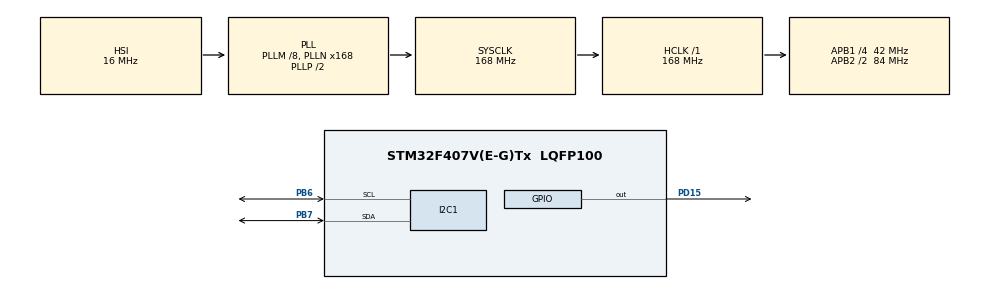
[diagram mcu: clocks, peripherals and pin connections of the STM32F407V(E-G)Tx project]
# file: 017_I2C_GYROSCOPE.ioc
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I2C1.I2C_Mode=I2C_Fast
Mcu.Family=STM32F4
Mcu.Name=STM32F407V(E-G)Tx
Mcu.Package=LQFP100
NVIC.PriorityGroup=NVIC_PRIORITYGROUP_4
PB6.Mode=I2C
PB6.Signal=I2C1_SCL
PB7.Mode=I2C
PB7.Signal=I2C1_SDA
PD15.Signal=GPIO_Output
ProjectManager.HeapSize=0x200
ProjectManager.StackSize=0x400
ProjectManager.TargetToolchain=STM32CubeIDE
RCC.48MHZClocksFreq_Value=84000000
RCC.AHBFreq_Value=168000000
RCC.APB1CLKDivider=RCC_HCLK_DIV4
RCC.APB1Freq_Value=42000000
RCC.APB1TimFreq_Value=84000000
RCC.APB2CLKDivider=RCC_HCLK_DIV2
RCC.APB2Freq_Value=84000000
RCC.APB2TimFreq_Value=168000000
RCC.CortexFreq_Value=168000000
RCC.HCLKFreq_Value=168000000
RCC.HSE_VALUE=25000000
RCC.HSI_VALUE=16000000
RCC.LSE_VALUE=32768
RCC.PLLM=8
RCC.PLLN=168
RCC.SYSCLKFreq_VALUE=168000000
RCC.SYSCLKSource=RCC_SYSCLKSOURCE_PLLCLK
RCC.VCOOutputFreq_Value=336000000
board=custom

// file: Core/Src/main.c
/* USER CODE BEGIN Header */
/**
  ******************************************************************************
  * @file           : main.c
  * @brief          : Main program body
  ******************************************************************************
  * @attention
  *
  * Copyright (c) 2023 STMicroelectronics.
  * All rights reserved.
  *
  * This software is licensed under terms that can be found in the LICENSE file
  * in the root directory of this software component.
  * If no LICENSE file comes with this software, it is provided AS-IS.
  *
  ******************************************************************************
  */
/* USER CODE END Header */
#include "main.h"

/* USER CODE BEGIN Includes */
uint8_t address;
uint8_t myDatas[6];

int16_t x,y,z;
float x_converted;

#define MPU6050_address 0xa6

/* USER CODE END Includes */

I2C_HandleTypeDef hi2c1;

/* USER CODE BEGIN PV */
void find_I2C_Address();
void MPU6050_Write(uint8_t wRegister, uint8_t value);
void MPU6050_Read(uint8_t rRegister, uint8_t numberOfBytes);
void MPU6050_Init();

uint8_t donustur(float A, int16_t B, int16_t C, float D, float E)
{
	return (float)(A-B) * (E-D) + D;
}

/* USER CODE END PV */

void SystemClock_Config(void);
static void MX_GPIO_Init(void);
static void MX_I2C1_Init(void);

int main(void)
{

  /* MCU Configuration--------------------------------------------------------*/

  /* Reset of all peripherals, Initializes the Flash interface and the Systick. */
  HAL_Init();

  /* Configure the system clock */
  SystemClock_Config();

  /* Initialize all configured peripherals */
  MX_GPIO_Init();
  MX_I2C1_Init();
  /* USER CODE BEGIN 2 */
  find_I2C_Address();
  MPU6050_Init();

  /* USER CODE END 2 */

  /* Infinite loop */
  while (1)
  {
	  MPU6050_Read(0x32, 6);

	  x = (myDatas[1] << 8  | myDatas[0]);
	  y = (myDatas[3] << 8  | myDatas[2]);
	  z = (myDatas[5] << 8  | myDatas[4]);

	  x_converted = donustur(x, -125, 125, 0, 360);

  }
}

void SystemClock_Config(void)
{
  RCC_OscInitTypeDef RCC_OscInitStruct = {0};
  RCC_ClkInitTypeDef RCC_ClkInitStruct = {0};

  /** Configure the main internal regulator output voltage
  */
  __HAL_RCC_PWR_CLK_ENABLE();
  __HAL_PWR_VOLTAGESCALING_CONFIG(PWR_REGULATOR_VOLTAGE_SCALE1);

  /** Initializes the RCC Oscillators according to the specified parameters
  * in the RCC_OscInitTypeDef structure.
  */
  RCC_OscInitStruct.OscillatorType = RCC_OSCILLATORTYPE_HSI;
  RCC_OscInitStruct.HSIState = RCC_HSI_ON;
  RCC_OscInitStruct.HSICalibrationValue = RCC_HSICALIBRATION_DEFAULT;
  RCC_OscInitStruct.PLL.PLLState = RCC_PLL_ON;
  RCC_OscInitStruct.PLL.PLLSource = RCC_PLLSOURCE_HSI;
  RCC_OscInitStruct.PLL.PLLM = 8;
  RCC_OscInitStruct.PLL.PLLN = 168;
  RCC_OscInitStruct.PLL.PLLP = RCC_PLLP_DIV2;
  RCC_OscInitStruct.PLL.PLLQ = 4;
  if (HAL_RCC_OscConfig(&RCC_OscInitStruct) != HAL_OK)
  {
    Error_Handler();
  }

  /** Initializes the CPU, AHB and APB buses clocks
  */
  RCC_ClkInitStruct.ClockType = RCC_CLOCKTYPE_HCLK|RCC_CLOCKTYPE_SYSCLK
                              |RCC_CLOCKTYPE_PCLK1|RCC_CLOCKTYPE_PCLK2;
  RCC_ClkInitStruct.SYSCLKSource = RCC_SYSCLKSOURCE_PLLCLK;
  RCC_ClkInitStruct.AHBCLKDivider = RCC_SYSCLK_DIV1;
  RCC_ClkInitStruct.APB1CLKDivider = RCC_HCLK_DIV4;
  RCC_ClkInitStruct.APB2CLKDivider = RCC_HCLK_DIV2;

  if (HAL_RCC_ClockConfig(&RCC_ClkInitStruct, FLASH_LATENCY_5) != HAL_OK)
  {
    Error_Handler();
  }
}

static void MX_I2C1_Init(void)
{

  hi2c1.Instance = I2C1;
  hi2c1.Init.ClockSpeed = 400000;
  hi2c1.Init.DutyCycle = I2C_DUTYCYCLE_2;
  hi2c1.Init.OwnAddress1 = 0;
  hi2c1.Init.AddressingMode = I2C_ADDRESSINGMODE_7BIT;
  hi2c1.Init.DualAddressMode = I2C_DUALADDRESS_DISABLE;
  hi2c1.Init.OwnAddress2 = 0;
  hi2c1.Init.GeneralCallMode = I2C_GENERALCALL_DISABLE;
  hi2c1.Init.NoStretchMode = I2C_NOSTRETCH_DISABLE;
  if (HAL_I2C_Init(&hi2c1) != HAL_OK)
  {
    Error_Handler();
  }

}

static void MX_GPIO_Init(void)
{
  GPIO_InitTypeDef GPIO_InitStruct = {0};

  /* GPIO Ports Clock Enable */
  __HAL_RCC_GPIOD_CLK_ENABLE();
  __HAL_RCC_GPIOB_CLK_ENABLE();

  /*Configure GPIO pin Output Level */
  HAL_GPIO_WritePin(GPIOD, GPIO_PIN_15, GPIO_PIN_RESET);

  /*Configure GPIO pin : PD15 */
  GPIO_InitStruct.Pin = GPIO_PIN_15;
  GPIO_InitStruct.Mode = GPIO_MODE_OUTPUT_PP;
  GPIO_InitStruct.Pull = GPIO_NOPULL;
  GPIO_InitStruct.Speed = GPIO_SPEED_FREQ_LOW;
  HAL_GPIO_Init(GPIOD, &GPIO_InitStruct);

}

/* USER CODE BEGIN 4 */
void find_I2C_Address()
{
	for(address = 0; address <= 255; address++)
	{
		if(HAL_I2C_IsDeviceReady(&hi2c1, address, 1, 100) == HAL_OK)
		{
			HAL_GPIO_TogglePin(GPIOD, GPIO_PIN_15);
			break;
		}
	}
}

void MPU6050_Write(uint8_t wRegister, uint8_t value)
{
	uint8_t data[2] ={0};
	data[0] = wRegister;
	data[1] = value;

	HAL_I2C_Master_Transmit(&hi2c1, MPU6050_address, data, 2, 100);
}

void MPU6050_Init()
{
	MPU6050_Read(0x00, 1);
	MPU6050_Write(0x2d, 0);
	MPU6050_Write(0x2d, 0x08);
	MPU6050_Write(0x31, 0x01);

}

void MPU6050_Read(uint8_t rRegister, uint8_t numberOfBytes)
{
	HAL_I2C_Mem_Read(&hi2c1, MPU6050_address, rRegister, 1, myDatas, numberOfBytes, 100);

}

/* USER CODE END 4 */

void Error_Handler(void)
{
  __disable_irq();
  while (1)
  {
  }
}
